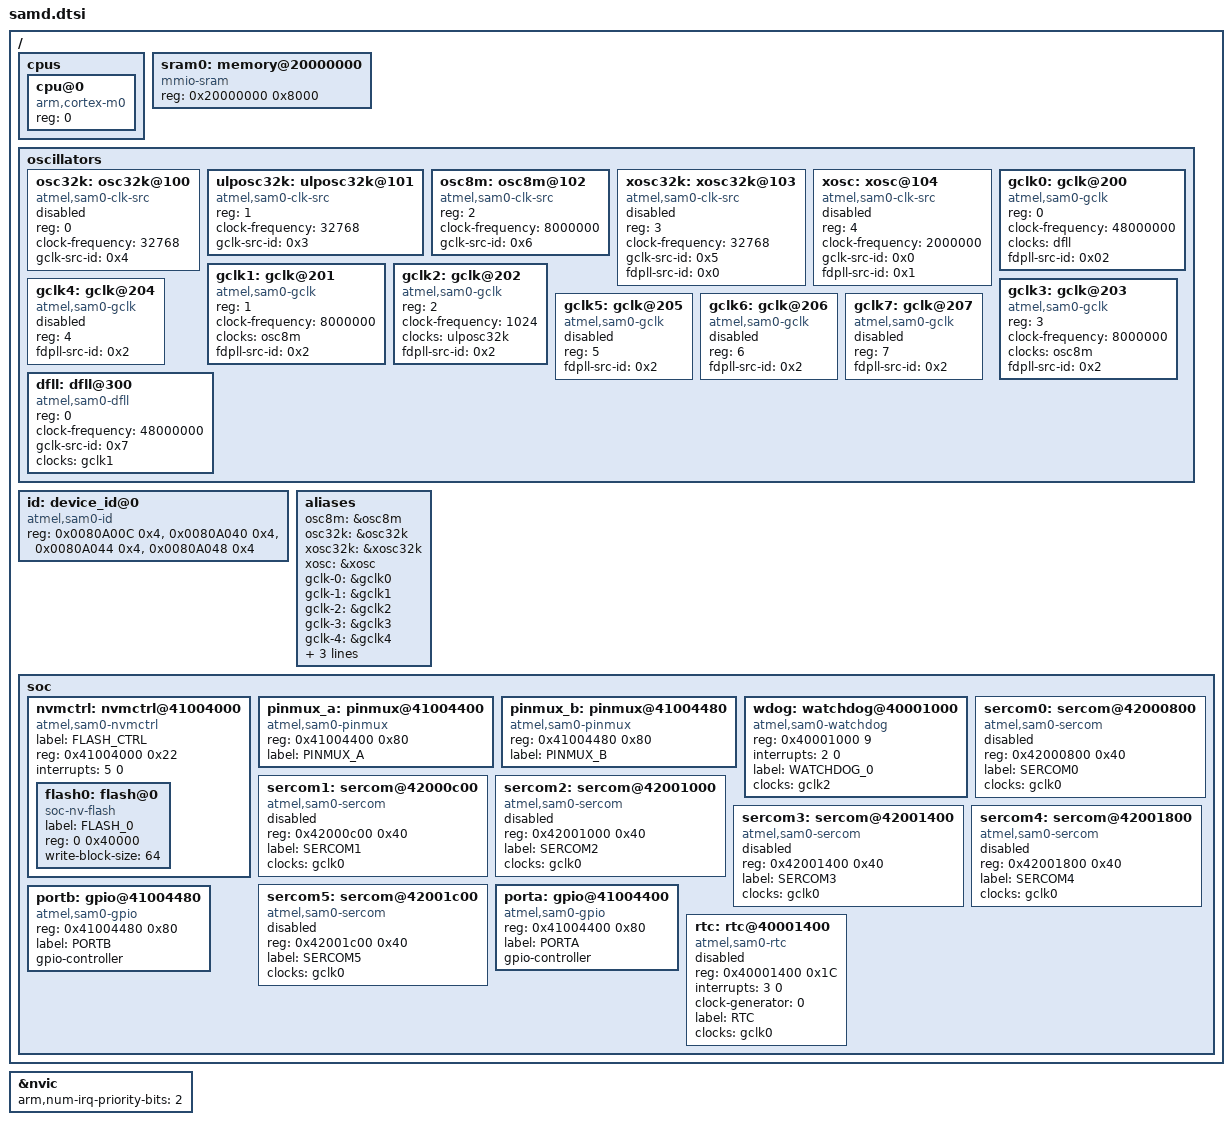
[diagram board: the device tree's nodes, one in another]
/*
 * Copyright (c) 2017 Google LLC.
 *
 * SPDX-License-Identifier: Apache-2.0
 */

#include <arm/armv6-m.dtsi>
#include <dt-bindings/gpio/gpio.h>

/ {
	cpus {
		#address-cells = <1>;
		#size-cells = <0>;

		cpu@0 {
			device_type = "cpu";
			compatible = "arm,cortex-m0";
			reg = <0>;
		};
	};

	sram0: memory@20000000 {
		device_type = "memory";
		compatible = "mmio-sram";
		reg = <0x20000000 0x8000>;
	};

	oscillators {
		#address-cells = <1>;
		#size-cells = <0>;

		osc32k: osc32k@100 {
			compatible = "atmel,sam0-clk-src";
			reg = <0>;
			clock-frequency = <32768>;
			gclk-src-id = <0x4>;
			#clock-cells = <0>;
			status = "disabled";
		};

		ulposc32k: ulposc32k@101 {
			compatible = "atmel,sam0-clk-src";
			reg = <1>;
			clock-frequency = <32768>;
			gclk-src-id = <0x3>;
			#clock-cells = <0>;
		};

		osc8m: osc8m@102 {
			compatible = "atmel,sam0-clk-src";
			reg = <2>;
			clock-frequency = <8000000>;
			gclk-src-id = <0x6>;
			#clock-cells = <0>;
		};

		xosc32k: xosc32k@103 {
			compatible = "atmel,sam0-clk-src";
			reg = <3>;
			clock-frequency = <32768>;
			gclk-src-id = <0x5>;
			fdpll-src-id = <0x0>;
			#clock-cells = <0>;
			status = "disabled";
		};

		xosc: xosc@104 {
			compatible = "atmel,sam0-clk-src";
			reg = <4>;
			#clock-cells = <0>;
			clock-frequency = <2000000>;
			gclk-src-id = <0x0>;
			fdpll-src-id = <0x1>;
			status = "disabled";
		};

		gclk0: gclk@200 {
			compatible = "atmel,sam0-gclk";
			reg = <0>;
			clock-frequency = <48000000>;
			clocks = <&dfll>;
			fdpll-src-id = <0x02>;
			#clock-cells = <0>;
		};

		gclk1: gclk@201 {
			compatible = "atmel,sam0-gclk";
			reg = <1>;
			clock-frequency = <8000000>;
			clocks = <&osc8m>;
			fdpll-src-id = <0x2>;
			#clock-cells = <0>;
		};

		gclk2: gclk@202 {
			compatible = "atmel,sam0-gclk";
			reg = <2>;
			clock-frequency = <1024>;
			clocks = <&ulposc32k>;
			fdpll-src-id = <0x2>;
			#clock-cells = <0>;
		};

		gclk3: gclk@203 {
			compatible = "atmel,sam0-gclk";
			reg = <3>;
			clock-frequency = <8000000>;
			clocks = <&osc8m>;
			fdpll-src-id = <0x2>;
			#clock-cells = <0>;
		};

		gclk4: gclk@204 {
			compatible = "atmel,sam0-gclk";
			reg = <4>;
			fdpll-src-id = <0x2>;
			#clock-cells = <0>;
			status = "disabled";
		};

		gclk5: gclk@205 {
			compatible = "atmel,sam0-gclk";
			reg = <5>;
			fdpll-src-id = <0x2>;
			#clock-cells = <0>;
			status = "disabled";
		};

		gclk6: gclk@206 {
			compatible = "atmel,sam0-gclk";
			reg = <6>;
			fdpll-src-id = <0x2>;
			#clock-cells = <0>;
			status = "disabled";
		};

		gclk7: gclk@207 {
			compatible = "atmel,sam0-gclk";
			reg = <7>;
			fdpll-src-id = <0x2>;
			#clock-cells = <0>;
			status = "disabled";
		};

		dfll: dfll@300 {
			compatible = "atmel,sam0-dfll";
			reg = <0>;
			clock-frequency = <48000000>;
			gclk-src-id = <0x7>;
			clocks = <&gclk1>;
			#clock-cells = <0>;
		};
	};

	id: device_id@0 {
		compatible = "atmel,sam0-id";
		reg =	<0x0080A00C 0x4>,
			<0x0080A040 0x4>,
			<0x0080A044 0x4>,
			<0x0080A048 0x4>;
	};

	aliases {
		osc8m = &osc8m;
		osc32k = &osc32k;
		xosc32k = &xosc32k;
		xosc = &xosc;

		gclk-0 = &gclk0;
		gclk-1 = &gclk1;
		gclk-2 = &gclk2;
		gclk-3 = &gclk3;
		gclk-4 = &gclk4;
		gclk-5 = &gclk5;
		gclk-6 = &gclk6;
		gclk-7 = &gclk7;
	};

	soc {
		nvmctrl: nvmctrl@41004000  {
			compatible = "atmel,sam0-nvmctrl";
			label = "FLASH_CTRL";
			reg = <0x41004000 0x22>;
			interrupts = <5 0>;

			#address-cells = <1>;
			#size-cells = <1>;

			flash0: flash@0 {
				compatible = "soc-nv-flash";
				label = "FLASH_0";
				reg = <0 0x40000>;
				write-block-size = <64>;
			};
		};

		pinmux_a: pinmux@41004400 {
			compatible = "atmel,sam0-pinmux";
			reg = <0x41004400 0x80>;
			label = "PINMUX_A";
		};

		pinmux_b: pinmux@41004480 {
			compatible = "atmel,sam0-pinmux";
			reg = <0x41004480 0x80>;
			label = "PINMUX_B";
		};

		wdog: watchdog@40001000 {
			compatible = "atmel,sam0-watchdog";
			reg = <0x40001000 9>;
			interrupts = <2 0>;
			label = "WATCHDOG_0";
			clocks = <&gclk2>;
		};

		sercom0: sercom@42000800 {
			compatible = "atmel,sam0-sercom";
			reg = <0x42000800 0x40>;
			status = "disabled";
			label = "SERCOM0";
			clocks = <&gclk0>;
		};

		sercom1: sercom@42000c00 {
			compatible = "atmel,sam0-sercom";
			reg = <0x42000c00 0x40>;
			status = "disabled";
			label = "SERCOM1";
			clocks = <&gclk0>;
		};

		sercom2: sercom@42001000 {
			compatible = "atmel,sam0-sercom";
			reg = <0x42001000 0x40>;
			status = "disabled";
			label = "SERCOM2";
			clocks = <&gclk0>;
		};

		sercom3: sercom@42001400 {
			compatible = "atmel,sam0-sercom";
			reg = <0x42001400 0x40>;
			status = "disabled";
			label = "SERCOM3";
			clocks = <&gclk0>;
		};

		sercom4: sercom@42001800 {
			compatible = "atmel,sam0-sercom";
			reg = <0x42001800 0x40>;
			status = "disabled";
			label = "SERCOM4";
			clocks = <&gclk0>;
		};

		sercom5: sercom@42001c00 {
			compatible = "atmel,sam0-sercom";
			reg = <0x42001c00 0x40>;
			status = "disabled";
			label = "SERCOM5";
			clocks = <&gclk0>;
		};

		porta: gpio@41004400 {
			compatible = "atmel,sam0-gpio";
			reg = <0x41004400 0x80>;
			label = "PORTA";
			gpio-controller;
			#gpio-cells = <2>;
		};

		portb: gpio@41004480 {
			compatible = "atmel,sam0-gpio";
			reg = <0x41004480 0x80>;
			label = "PORTB";
			gpio-controller;
			#gpio-cells = <2>;
		};

		rtc: rtc@40001400 {
			compatible = "atmel,sam0-rtc";
			reg = <0x40001400 0x1C>;
			interrupts = <3 0>;
			clock-generator = <0>;
			status = "disabled";
			label = "RTC";
			clocks = <&gclk0>;
		};
	};
};

&nvic {
	arm,num-irq-priority-bits = <2>;
};
